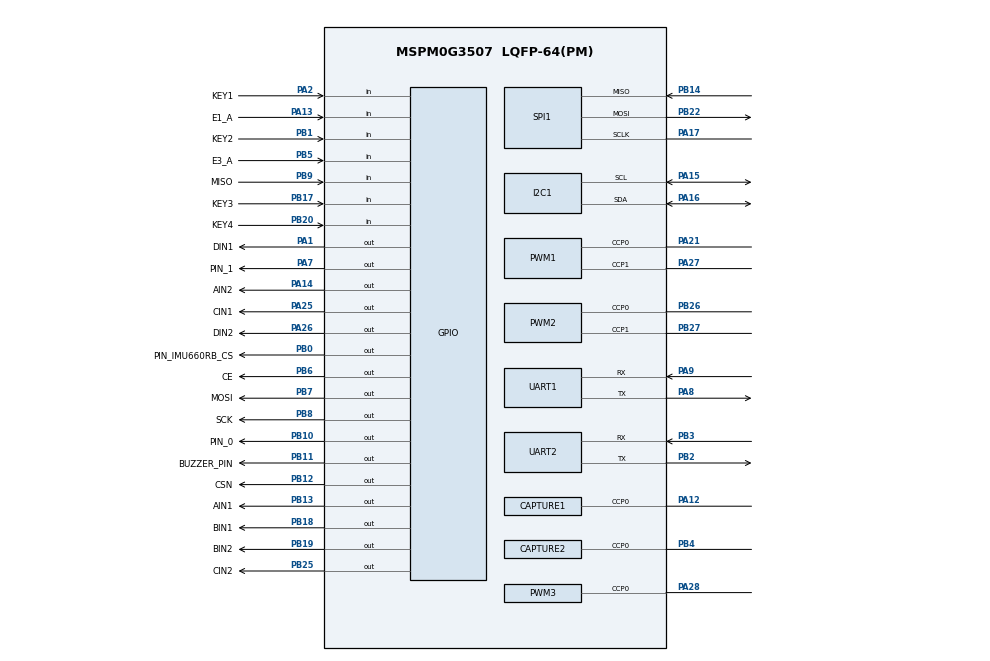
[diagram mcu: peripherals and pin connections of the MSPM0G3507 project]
/**
 * These arguments were used when this file was generated. They will be automatically applied on subsequent loads
 * via the GUI or CLI. Run CLI with '--help' for additional information on how to override these arguments.
 * @cliArgs --device "MSPM0G350X" --part "Default" --package "LQFP-64(PM)" --product "mspm0_sdk@2.10.00.04"
 * @v2CliArgs --device "MSPM0G3507" --package "LQFP-64(PM)" --product "mspm0_sdk@2.10.00.04"
 * @versions {"tool":"1.27.0+4565"}
 */

/**
 * Import the modules used in this configuration.
 */
const CAPTURE  = scripting.addModule("/ti/driverlib/CAPTURE", {}, false);
const CAPTURE1 = CAPTURE.addInstance();
const CAPTURE2 = CAPTURE.addInstance();
const DMA      = scripting.addModule("/ti/driverlib/DMA");
const GPIO     = scripting.addModule("/ti/driverlib/GPIO", {}, false);
const GPIO1    = GPIO.addInstance();
const GPIO2    = GPIO.addInstance();
const GPIO3    = GPIO.addInstance();
const GPIO4    = GPIO.addInstance();
const GPIO5    = GPIO.addInstance();
const GPIO6    = GPIO.addInstance();
const GPIO7    = GPIO.addInstance();
const GPIO8    = GPIO.addInstance();
const I2C      = scripting.addModule("/ti/driverlib/I2C", {}, false);
const I2C1     = I2C.addInstance();
const PWM      = scripting.addModule("/ti/driverlib/PWM", {}, false);
const PWM1     = PWM.addInstance();
const PWM2     = PWM.addInstance();
const PWM3     = PWM.addInstance();
const SPI      = scripting.addModule("/ti/driverlib/SPI", {}, false);
const SPI1     = SPI.addInstance();
const SYSCTL   = scripting.addModule("/ti/driverlib/SYSCTL");
const TIMER    = scripting.addModule("/ti/driverlib/TIMER", {}, false);
const TIMER1   = TIMER.addInstance();
const UART     = scripting.addModule("/ti/driverlib/UART", {}, false);
const UART1    = UART.addInstance();
const UART2    = UART.addInstance();

/**
 * Write custom configuration values to the imported modules.
 */
CAPTURE1.timerPeriod                        = "1ms";
CAPTURE1.interrupts                         = ["CC0_DN"];
CAPTURE1.multi_countRep                     = "DL_TIMER_REPEAT_MODE_ENABLED";
CAPTURE1.$name                              = "E1_B";
CAPTURE1.peripheral.ccp0Pin.$assign         = "PA12";
CAPTURE1.ccp0PinConfig.hideOutputInversion  = scripting.forceWrite(false);
CAPTURE1.ccp0PinConfig.onlyInternalResistor = scripting.forceWrite(false);
CAPTURE1.ccp0PinConfig.passedPeripheralType = scripting.forceWrite("Digital");
CAPTURE1.ccp0PinConfig.$name                = "ti_driverlib_gpio_GPIOPinGeneric8";

const Board = scripting.addModule("/ti/driverlib/Board", {}, false);

CAPTURE2.timerPeriod                        = "1 ms";
CAPTURE2.interrupts                         = ["CC0_DN"];
CAPTURE2.$name                              = "E3_B";
CAPTURE2.timerClkDiv                        = 2;
CAPTURE2.peripheral.ccp0Pin.$assign         = "PB4";
CAPTURE2.ccp0PinConfig.hideOutputInversion  = scripting.forceWrite(false);
CAPTURE2.ccp0PinConfig.onlyInternalResistor = scripting.forceWrite(false);
CAPTURE2.ccp0PinConfig.passedPeripheralType = scripting.forceWrite("Digital");
CAPTURE2.ccp0PinConfig.$name                = "ti_driverlib_gpio_GPIOPinGeneric10";

GPIO1.$name                         = "ECO";
GPIO1.associatedPins.create(2);
GPIO1.associatedPins[0].$name       = "E1_A";
GPIO1.associatedPins[0].direction   = "INPUT";
GPIO1.associatedPins[0].pin.$assign = "PA13";
GPIO1.associatedPins[1].$name       = "E3_A";
GPIO1.associatedPins[1].direction   = "INPUT";
GPIO1.associatedPins[1].pin.$assign = "PB5";

GPIO2.$name                         = "DIR";
GPIO2.associatedPins.create(8);
GPIO2.associatedPins[0].$name       = "AIN1";
GPIO2.associatedPins[0].pin.$assign = "PB13";
GPIO2.associatedPins[1].$name       = "AIN2";
GPIO2.associatedPins[1].pin.$assign = "PA14";
GPIO2.associatedPins[2].$name       = "BIN1";
GPIO2.associatedPins[2].pin.$assign = "PB18";
GPIO2.associatedPins[3].$name       = "BIN2";
GPIO2.associatedPins[3].pin.$assign = "PB19";
GPIO2.associatedPins[4].$name       = "CIN1";
GPIO2.associatedPins[4].pin.$assign = "PA25";
GPIO2.associatedPins[5].$name       = "CIN2";
GPIO2.associatedPins[5].pin.$assign = "PB25";
GPIO2.associatedPins[6].$name       = "DIN1";
GPIO2.associatedPins[6].pin.$assign = "PA1";
GPIO2.associatedPins[7].$name       = "DIN2";
GPIO2.associatedPins[7].pin.$assign = "PA26";

GPIO3.$name                         = "GPIO_IMU660RB";
GPIO3.associatedPins[0].$name       = "PIN_IMU660RB_CS";
GPIO3.associatedPins[0].pin.$assign = "PB0";

GPIO4.$name                              = "KEY";
GPIO4.associatedPins.create(4);
GPIO4.associatedPins[0].$name            = "KEY1";
GPIO4.associatedPins[0].direction        = "INPUT";
GPIO4.associatedPins[0].internalResistor = "PULL_UP";
GPIO4.associatedPins[0].pin.$assign      = "PA2";
GPIO4.associatedPins[1].$name            = "KEY2";
GPIO4.associatedPins[1].direction        = "INPUT";
GPIO4.associatedPins[1].internalResistor = "PULL_UP";
GPIO4.associatedPins[1].pin.$assign      = "PB1";
GPIO4.associatedPins[2].$name            = "KEY3";
GPIO4.associatedPins[2].direction        = "INPUT";
GPIO4.associatedPins[2].internalResistor = "PULL_UP";
GPIO4.associatedPins[2].pin.$assign      = "PB17";
GPIO4.associatedPins[3].$name            = "KEY4";
GPIO4.associatedPins[3].direction        = "INPUT";
GPIO4.associatedPins[3].internalResistor = "PULL_UP";
GPIO4.associatedPins[3].pin.$assign      = "PB20";

GPIO5.$name                         = "USER_SPI";
GPIO5.associatedPins.create(5);
GPIO5.associatedPins[0].$name       = "CSN";
GPIO5.associatedPins[0].pin.$assign = "PB12";
GPIO5.associatedPins[1].$name       = "CE";
GPIO5.associatedPins[1].pin.$assign = "PB6";
GPIO5.associatedPins[2].$name       = "MOSI";
GPIO5.associatedPins[2].pin.$assign = "PB7";
GPIO5.associatedPins[3].$name       = "SCK";
GPIO5.associatedPins[3].pin.$assign = "PB8";
GPIO5.associatedPins[4].$name       = "MISO";
GPIO5.associatedPins[4].direction   = "INPUT";
GPIO5.associatedPins[4].pin.$assign = "PB9";

GPIO6.$name                          = "BUZZER";
GPIO6.associatedPins[0].$name        = "BUZZER_PIN";
GPIO6.associatedPins[0].initialValue = "SET";
GPIO6.associatedPins[0].pin.$assign  = "PB11";

GPIO7.$name                         = "CITIE";
GPIO7.associatedPins[0].$name       = "PIN_0";
GPIO7.associatedPins[0].pin.$assign = "PB10";

GPIO8.$name                         = "LED";
GPIO8.associatedPins[0].$name       = "PIN_1";
GPIO8.associatedPins[0].pin.$assign = "PA7";

I2C1.basicEnableController             = true;
I2C1.$name                             = "I2C_OLED";
I2C1.basicControllerStandardBusSpeed   = "FastPlus";
I2C1.peripheral.sdaPin.$assign         = "PA16";
I2C1.peripheral.sclPin.$assign         = "PA15";
I2C1.sdaPinConfig.hideOutputInversion  = scripting.forceWrite(false);
I2C1.sdaPinConfig.onlyInternalResistor = scripting.forceWrite(false);
I2C1.sdaPinConfig.passedPeripheralType = scripting.forceWrite("Digital");
I2C1.sdaPinConfig.$name                = "ti_driverlib_gpio_GPIOPinGeneric4";
I2C1.sclPinConfig.hideOutputInversion  = scripting.forceWrite(false);
I2C1.sclPinConfig.onlyInternalResistor = scripting.forceWrite(false);
I2C1.sclPinConfig.passedPeripheralType = scripting.forceWrite("Digital");
I2C1.sclPinConfig.$name                = "ti_driverlib_gpio_GPIOPinGeneric5";

PWM1.$name                      = "PWM_0";
PWM1.timerStartTimer            = true;
PWM1.pwmMode                    = "EDGE_ALIGN_UP";
PWM1.peripheral.$assign         = "TIMG8";
PWM1.peripheral.ccp0Pin.$assign = "PA21";
PWM1.peripheral.ccp1Pin.$assign = "PA27";
PWM1.PWM_CHANNEL_0.$name        = "ti_driverlib_pwm_PWMTimerCC0";
PWM1.PWM_CHANNEL_1.$name        = "ti_driverlib_pwm_PWMTimerCC2";
PWM1.ccp0PinConfig.$name        = "ti_driverlib_gpio_GPIOPinGeneric1";
PWM1.ccp1PinConfig.$name        = "ti_driverlib_gpio_GPIOPinGeneric0";

PWM2.$name                      = "PWM_1";
PWM2.timerStartTimer            = true;
PWM2.pwmMode                    = "EDGE_ALIGN_UP";
PWM2.peripheral.$assign         = "TIMG6";
PWM2.peripheral.ccp0Pin.$assign = "PB26";
PWM2.peripheral.ccp1Pin.$assign = "PB27";
PWM2.PWM_CHANNEL_0.$name        = "ti_driverlib_pwm_PWMTimerCC1";
PWM2.PWM_CHANNEL_1.$name        = "ti_driverlib_pwm_PWMTimerCC3";
PWM2.ccp0PinConfig.$name        = "ti_driverlib_gpio_GPIOPinGeneric6";
PWM2.ccp1PinConfig.$name        = "ti_driverlib_gpio_GPIOPinGeneric7";

PWM3.$name                              = "PWM_SERVO";
PWM3.timerStartTimer                    = true;
PWM3.pwmMode                            = "EDGE_ALIGN_UP";
PWM3.clockPrescale                      = 8;
PWM3.timerCount                         = 20000;
PWM3.peripheral.$assign                 = "TIMG7";
PWM3.peripheral.ccp0Pin.$assign         = "PA28";
PWM3.PWM_CHANNEL_0.$name                = "ti_driverlib_pwm_PWMTimerCC4";
PWM3.PWM_CHANNEL_1.$name                = "ti_driverlib_pwm_PWMTimerCC5";
PWM3.ccp0PinConfig.direction            = scripting.forceWrite("OUTPUT");
PWM3.ccp0PinConfig.hideOutputInversion  = scripting.forceWrite(false);
PWM3.ccp0PinConfig.onlyInternalResistor = scripting.forceWrite(false);
PWM3.ccp0PinConfig.passedPeripheralType = scripting.forceWrite("Digital");
PWM3.ccp0PinConfig.$name                = "ti_driverlib_gpio_GPIOPinGeneric15";
PWM3.ccp1PinConfig.direction            = scripting.forceWrite("OUTPUT");
PWM3.ccp1PinConfig.hideOutputInversion  = scripting.forceWrite(false);
PWM3.ccp1PinConfig.onlyInternalResistor = scripting.forceWrite(false);
PWM3.ccp1PinConfig.passedPeripheralType = scripting.forceWrite("Digital");
PWM3.ccp1PinConfig.$name                = "ti_driverlib_gpio_GPIOPinGeneric16";

SPI1.$name                              = "SPI_IMU660RB";
SPI1.frameFormat                        = "MOTO3";
SPI1.sclkPinConfig.direction            = scripting.forceWrite("OUTPUT");
SPI1.sclkPinConfig.onlyInternalResistor = scripting.forceWrite(false);
SPI1.sclkPinConfig.passedPeripheralType = scripting.forceWrite("Digital");
SPI1.sclkPinConfig.$name                = "ti_driverlib_gpio_GPIOPinGeneric9";
SPI1.mosiPinConfig.$name                = "ti_driverlib_gpio_GPIOPinGeneric11";
SPI1.mosiPinConfig.direction            = scripting.forceWrite("OUTPUT");
SPI1.mosiPinConfig.hideOutputInversion  = scripting.forceWrite(false);
SPI1.mosiPinConfig.onlyInternalResistor = scripting.forceWrite(false);
SPI1.mosiPinConfig.passedPeripheralType = scripting.forceWrite("Digital");
SPI1.misoPinConfig.$name                = "ti_driverlib_gpio_GPIOPinGeneric12";
SPI1.misoPinConfig.onlyInternalResistor = scripting.forceWrite(false);
SPI1.misoPinConfig.passedPeripheralType = scripting.forceWrite("Digital");
SPI1.peripheral.sclkPin.$assign         = "PA17";
SPI1.peripheral.mosiPin.$assign         = "PB22";
SPI1.peripheral.misoPin.$assign         = "PB14";

SYSCTL.SYSPLL_CLK2XEn     = true;
SYSCTL.SYSPLL_Pdiv        = 1;
SYSCTL.SYSPLL_Qdiv        = 5;
SYSCTL.SYSPLL_CLK2XDiv    = 3;
SYSCTL.MCLKSource         = "HSCLK";
SYSCTL.HSCLKSource        = "SYSPLLCLK2X";
SYSCTL.validateClkStatus  = true;
SYSCTL.MFPCLKEn           = true;
SYSCTL.UDIV               = "2";
SYSCTL.peripheral.$assign = "SYSCTL";

TIMER1.$name           = "TIMER_0";
TIMER1.timerMode       = "PERIODIC";
TIMER1.timerPeriod     = "1 ms";
TIMER1.timerStartTimer = true;
TIMER1.interrupts      = ["ZERO"];
TIMER1.timerClkDiv     = 2;

UART1.$name                    = "UART_0";
UART1.targetBaudRate           = 115200;
UART1.enabledInterrupts        = ["RX"];
UART1.peripheral.rxPin.$assign = "PA9";
UART1.peripheral.txPin.$assign = "PA8";
UART1.txPinConfig.$name        = "ti_driverlib_gpio_GPIOPinGeneric2";
UART1.rxPinConfig.$name        = "ti_driverlib_gpio_GPIOPinGeneric3";

UART2.$name                    = "UART_1";
UART2.targetBaudRate           = 115200;
UART2.peripheral.rxPin.$assign = "PB3";
UART2.peripheral.txPin.$assign = "PB2";
UART2.txPinConfig.$name        = "ti_driverlib_gpio_GPIOPinGeneric13";
UART2.rxPinConfig.$name        = "ti_driverlib_gpio_GPIOPinGeneric14";

/**
 * Pinmux solution for unlocked pins/peripherals. This ensures that minor changes to the automatic solver in a future
 * version of the tool will not impact the pinmux you originally saw.  These lines can be completely deleted in order to
 * re-solve from scratch.
 */
CAPTURE1.peripheral.$suggestSolution       = "TIMG0";
Board.peripheral.$suggestSolution          = "DEBUGSS";
Board.peripheral.swclkPin.$suggestSolution = "PA20";
Board.peripheral.swdioPin.$suggestSolution = "PA19";
CAPTURE2.peripheral.$suggestSolution       = "TIMA1";
I2C1.peripheral.$suggestSolution           = "I2C1";
PWM3.peripheral.ccp1Pin.$suggestSolution   = "PA18";
SPI1.peripheral.$suggestSolution           = "SPI1";
TIMER1.peripheral.$suggestSolution         = "TIMA0";
UART1.peripheral.$suggestSolution          = "UART1";
UART2.peripheral.$suggestSolution          = "UART3";
